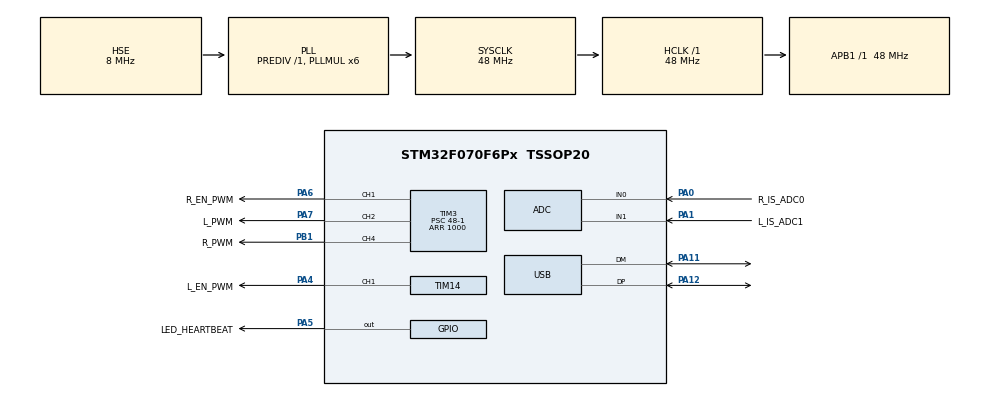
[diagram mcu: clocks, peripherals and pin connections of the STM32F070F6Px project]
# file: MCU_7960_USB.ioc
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ADC.ClockPrescaler=ADC_CLOCK_SYNC_PCLK_DIV4
ADC.ContinuousConvMode=DISABLE
ADC.ExternalTrigConv=ADC_SOFTWARE_START
ADC.ExternalTrigConvEdge=ADC_EXTERNALTRIGCONVEDGE_NONE
ADC.Overrun=ADC_OVR_DATA_OVERWRITTEN
Mcu.Family=STM32F0
Mcu.Name=STM32F070F6Px
Mcu.Package=TSSOP20
NVIC.ADC1_IRQn=true\:0\:0\:false\:false\:true\:true\:true\:true
NVIC.TIM3_IRQn=true\:0\:0\:false\:false\:true\:true\:true\:true
NVIC.USB_IRQn=true\:0\:0\:false\:false\:true\:false\:true\:true
PA0.GPIO_Label=R_IS_ADC0
PA0.Mode=IN0
PA0.Signal=ADC_IN0
PA1.GPIO_Label=L_IS_ADC1
PA1.Mode=IN1
PA1.Signal=ADC_IN1
PA11.Mode=Device
PA11.Signal=USB_DM
PA12.Mode=Device
PA12.Signal=USB_DP
PA13.Mode=Serial_Wire
PA13.Signal=SYS_SWDIO
PA14.Mode=Serial_Wire
PA14.Signal=SYS_SWCLK
PA4.GPIO_Label=L_EN_PWM
PA4.Signal=S_TIM14_CH1
PA5.GPIO_Label=LED_HEARTBEAT
PA5.GPIO_ModeDefaultOutputPP=GPIO_MODE_OUTPUT_OD
PA5.GPIO_PuPd=GPIO_NOPULL
PA5.Signal=GPIO_Output
PA6.GPIO_Label=R_EN_PWM
PA6.Signal=S_TIM3_CH1
PA7.GPIO_Label=L_PWM
PA7.Signal=S_TIM3_CH2
PB1.GPIO_Label=R_PWM
PB1.Signal=S_TIM3_CH4
PF0-OSC_IN.Mode=HSE-External-Oscillator
PF0-OSC_IN.Signal=RCC_OSC_IN
PF1-OSC_OUT.Mode=HSE-External-Oscillator
PF1-OSC_OUT.Signal=RCC_OSC_OUT
ProjectManager.HeapSize=0x150
ProjectManager.StackSize=0x300
ProjectManager.TargetToolchain=Makefile
RCC.AHBFreq_Value=48000000
RCC.APB1Freq_Value=48000000
RCC.APB1TimFreq_Value=48000000
RCC.HCLKFreq_Value=48000000
RCC.PLLMUL=RCC_PLL_MUL6
RCC.SYSCLKFreq_VALUE=48000000
RCC.SYSCLKSource=RCC_SYSCLKSOURCE_PLLCLK
SH.S_TIM14_CH1.0=TIM14_CH1,PWM Generation1 CH1
SH.S_TIM3_CH1.0=TIM3_CH1,PWM Generation1 CH1
SH.S_TIM3_CH2.0=TIM3_CH2,PWM Generation2 CH2
SH.S_TIM3_CH4.0=TIM3_CH4,PWM Generation4 CH4
TIM1.AutoReloadPreload=TIM_AUTORELOAD_PRELOAD_ENABLE
TIM1.Period=5000
TIM1.Prescaler=48-1
TIM14.AutoReloadPreload=TIM_AUTORELOAD_PRELOAD_ENABLE
TIM14.Channel=TIM_CHANNEL_1
TIM14.OCPolarity_1=TIM_OCPOLARITY_LOW
TIM14.Period=1000
TIM14.Prescaler=48-1
TIM3.AutoReloadPreload=TIM_AUTORELOAD_PRELOAD_ENABLE
TIM3.Channel-PWM\ Generation1\ CH1=TIM_CHANNEL_1
TIM3.Channel-PWM\ Generation2\ CH2=TIM_CHANNEL_2
TIM3.Channel-PWM\ Generation4\ CH4=TIM_CHANNEL_4
TIM3.OCPolarity_1=TIM_OCPOLARITY_LOW
TIM3.OCPolarity_4=TIM_OCPOLARITY_LOW
TIM3.Period=1000
TIM3.Prescaler=48-1
USB_DEVICE.APP_RX_DATA_SIZE=512
USB_DEVICE.APP_TX_DATA_SIZE=512
USB_DEVICE.CLASS_NAME_FS=CDC
USB_DEVICE.VirtualMode=Cdc
USB_DEVICE.VirtualModeFS=Cdc_FS
VP_SYS_VS_PINREMAP.Mode=PINREMAP
VP_TIM14_VS_ClockSourceINT.Mode=Enable_Timer
VP_TIM1_VS_ClockSourceINT.Mode=Internal
VP_TIM3_VS_ClockSourceINT.Mode=Internal
VP_USB_DEVICE_VS_USB_DEVICE_CDC_FS.Mode=CDC_FS
VP_WWDG_VS_WWDG.Mode=WWDG_Activate
WWDG.Prescaler=WWDG_PRESCALER_8
board=custom

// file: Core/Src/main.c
/* USER CODE BEGIN Header */
/**
  ******************************************************************************
  * @file           : main.c
  * @brief          : Main program body
  ******************************************************************************
  * @attention
  *
  * Copyright (c) 2024 STMicroelectronics.
  * All rights reserved.
  *
  * This software is licensed under terms that can be found in the LICENSE file
  * in the root directory of this software component.
  * If no LICENSE file comes with this software, it is provided AS-IS.
  *
  ******************************************************************************
  */
/* USER CODE END Header */
#include "main.h"
#include "usb_device.h"

/* USER CODE BEGIN Includes */
#include "Comms_Controller.h"
#include "MCU_7960_USB.h"
/* USER CODE END Includes */

ADC_HandleTypeDef hadc;

TIM_HandleTypeDef htim1;
TIM_HandleTypeDef htim3;
TIM_HandleTypeDef htim14;

WWDG_HandleTypeDef hwwdg;

void SystemClock_Config(void);
static void MX_GPIO_Init(void);
static void MX_ADC_Init(void);
static void MX_TIM3_Init(void);
static void MX_TIM14_Init(void);
static void MX_TIM1_Init(void);

int main(void)
{

  /* MCU Configuration--------------------------------------------------------*/

  /* Reset of all peripherals, Initializes the Flash interface and the Systick. */
  HAL_Init();

  /* Configure the system clock */
  SystemClock_Config();

  /* USER CODE BEGIN SysInit */
  MX_GPIO_Init();
  Comms_Controller_Reset_USB();

  /* USER CODE END SysInit */

  /* Initialize all configured peripherals */
  MX_ADC_Init();
  MX_TIM3_Init();
  MX_TIM14_Init();
  MX_USB_DEVICE_Init();
  MX_TIM1_Init();
  /* USER CODE BEGIN 2 */
  MCU_7960_USB_Initialise();
  HAL_TIM_Base_Start_IT(&htim3);

  /* USER CODE END 2 */

  /* Infinite loop */
  while (1)
  {

    /* USER CODE BEGIN 3 */
    MCU_7960_USB_Main();

  }
  /* USER CODE END 3 */
}

void SystemClock_Config(void)
{
  RCC_OscInitTypeDef RCC_OscInitStruct = {0};
  RCC_ClkInitTypeDef RCC_ClkInitStruct = {0};
  RCC_PeriphCLKInitTypeDef PeriphClkInit = {0};

  /** Initializes the RCC Oscillators according to the specified parameters
  * in the RCC_OscInitTypeDef structure.
  */
  RCC_OscInitStruct.OscillatorType = RCC_OSCILLATORTYPE_HSE;
  RCC_OscInitStruct.HSEState = RCC_HSE_ON;
  RCC_OscInitStruct.PLL.PLLState = RCC_PLL_ON;
  RCC_OscInitStruct.PLL.PLLSource = RCC_PLLSOURCE_HSE;
  RCC_OscInitStruct.PLL.PLLMUL = RCC_PLL_MUL6;
  RCC_OscInitStruct.PLL.PREDIV = RCC_PREDIV_DIV1;
  if (HAL_RCC_OscConfig(&RCC_OscInitStruct) != HAL_OK)
  {
    Error_Handler();
  }

  /** Initializes the CPU, AHB and APB buses clocks
  */
  RCC_ClkInitStruct.ClockType = RCC_CLOCKTYPE_HCLK|RCC_CLOCKTYPE_SYSCLK
                              |RCC_CLOCKTYPE_PCLK1;
  RCC_ClkInitStruct.SYSCLKSource = RCC_SYSCLKSOURCE_PLLCLK;
  RCC_ClkInitStruct.AHBCLKDivider = RCC_SYSCLK_DIV1;
  RCC_ClkInitStruct.APB1CLKDivider = RCC_HCLK_DIV1;

  if (HAL_RCC_ClockConfig(&RCC_ClkInitStruct, FLASH_LATENCY_1) != HAL_OK)
  {
    Error_Handler();
  }
  PeriphClkInit.PeriphClockSelection = RCC_PERIPHCLK_USB;
  PeriphClkInit.UsbClockSelection = RCC_USBCLKSOURCE_PLL;

  if (HAL_RCCEx_PeriphCLKConfig(&PeriphClkInit) != HAL_OK)
  {
    Error_Handler();
  }
}

static void MX_ADC_Init(void)
{

  ADC_ChannelConfTypeDef sConfig = {0};

  /** Configure the global features of the ADC (Clock, Resolution, Data Alignment and number of conversion)
  */
  hadc.Instance = ADC1;
  hadc.Init.ClockPrescaler = ADC_CLOCK_SYNC_PCLK_DIV4;
  hadc.Init.Resolution = ADC_RESOLUTION_12B;
  hadc.Init.DataAlign = ADC_DATAALIGN_RIGHT;
  hadc.Init.ScanConvMode = ADC_SCAN_DIRECTION_FORWARD;
  hadc.Init.EOCSelection = ADC_EOC_SINGLE_CONV;
  hadc.Init.LowPowerAutoWait = DISABLE;
  hadc.Init.LowPowerAutoPowerOff = DISABLE;
  hadc.Init.ContinuousConvMode = DISABLE;
  hadc.Init.DiscontinuousConvMode = DISABLE;
  hadc.Init.ExternalTrigConv = ADC_SOFTWARE_START;
  hadc.Init.ExternalTrigConvEdge = ADC_EXTERNALTRIGCONVEDGE_NONE;
  hadc.Init.DMAContinuousRequests = DISABLE;
  hadc.Init.Overrun = ADC_OVR_DATA_OVERWRITTEN;
  if (HAL_ADC_Init(&hadc) != HAL_OK)
  {
    Error_Handler();
  }

  /** Configure for the selected ADC regular channel to be converted.
  */
  sConfig.Channel = ADC_CHANNEL_0;
  sConfig.Rank = ADC_RANK_CHANNEL_NUMBER;
  sConfig.SamplingTime = ADC_SAMPLETIME_1CYCLE_5;
  if (HAL_ADC_ConfigChannel(&hadc, &sConfig) != HAL_OK)
  {
    Error_Handler();
  }

  /** Configure for the selected ADC regular channel to be converted.
  */
  sConfig.Channel = ADC_CHANNEL_1;
  if (HAL_ADC_ConfigChannel(&hadc, &sConfig) != HAL_OK)
  {
    Error_Handler();
  }
  /* USER CODE BEGIN ADC_Init 2 */
  HAL_ADC_Start_IT(&hadc);  // start the sequence conversions

  /* USER CODE END ADC_Init 2 */

}

static void MX_TIM1_Init(void)
{

  TIM_ClockConfigTypeDef sClockSourceConfig = {0};
  TIM_MasterConfigTypeDef sMasterConfig = {0};

  htim1.Instance = TIM1;
  htim1.Init.Prescaler = 48-1;
  htim1.Init.CounterMode = TIM_COUNTERMODE_UP;
  htim1.Init.Period = 5000;
  htim1.Init.ClockDivision = TIM_CLOCKDIVISION_DIV1;
  htim1.Init.RepetitionCounter = 0;
  htim1.Init.AutoReloadPreload = TIM_AUTORELOAD_PRELOAD_ENABLE;
  if (HAL_TIM_Base_Init(&htim1) != HAL_OK)
  {
    Error_Handler();
  }
  sClockSourceConfig.ClockSource = TIM_CLOCKSOURCE_INTERNAL;
  if (HAL_TIM_ConfigClockSource(&htim1, &sClockSourceConfig) != HAL_OK)
  {
    Error_Handler();
  }
  sMasterConfig.MasterOutputTrigger = TIM_TRGO_RESET;
  sMasterConfig.MasterSlaveMode = TIM_MASTERSLAVEMODE_DISABLE;
  if (HAL_TIMEx_MasterConfigSynchronization(&htim1, &sMasterConfig) != HAL_OK)
  {
    Error_Handler();
  }

}

static void MX_TIM3_Init(void)
{

  TIM_ClockConfigTypeDef sClockSourceConfig = {0};
  TIM_MasterConfigTypeDef sMasterConfig = {0};
  TIM_OC_InitTypeDef sConfigOC = {0};

  htim3.Instance = TIM3;
  htim3.Init.Prescaler = 48-1;
  htim3.Init.CounterMode = TIM_COUNTERMODE_UP;
  htim3.Init.Period = 1000;
  htim3.Init.ClockDivision = TIM_CLOCKDIVISION_DIV1;
  htim3.Init.AutoReloadPreload = TIM_AUTORELOAD_PRELOAD_ENABLE;
  if (HAL_TIM_Base_Init(&htim3) != HAL_OK)
  {
    Error_Handler();
  }
  sClockSourceConfig.ClockSource = TIM_CLOCKSOURCE_INTERNAL;
  if (HAL_TIM_ConfigClockSource(&htim3, &sClockSourceConfig) != HAL_OK)
  {
    Error_Handler();
  }
  if (HAL_TIM_PWM_Init(&htim3) != HAL_OK)
  {
    Error_Handler();
  }
  sMasterConfig.MasterOutputTrigger = TIM_TRGO_RESET;
  sMasterConfig.MasterSlaveMode = TIM_MASTERSLAVEMODE_DISABLE;
  if (HAL_TIMEx_MasterConfigSynchronization(&htim3, &sMasterConfig) != HAL_OK)
  {
    Error_Handler();
  }
  sConfigOC.OCMode = TIM_OCMODE_PWM1;
  sConfigOC.Pulse = 0;
  sConfigOC.OCPolarity = TIM_OCPOLARITY_LOW;
  sConfigOC.OCFastMode = TIM_OCFAST_DISABLE;
  if (HAL_TIM_PWM_ConfigChannel(&htim3, &sConfigOC, TIM_CHANNEL_1) != HAL_OK)
  {
    Error_Handler();
  }
  sConfigOC.OCPolarity = TIM_OCPOLARITY_HIGH;
  if (HAL_TIM_PWM_ConfigChannel(&htim3, &sConfigOC, TIM_CHANNEL_2) != HAL_OK)
  {
    Error_Handler();
  }
  sConfigOC.OCPolarity = TIM_OCPOLARITY_LOW;
  if (HAL_TIM_PWM_ConfigChannel(&htim3, &sConfigOC, TIM_CHANNEL_4) != HAL_OK)
  {
    Error_Handler();
  }
  HAL_TIM_MspPostInit(&htim3);

}

static void MX_TIM14_Init(void)
{

  TIM_OC_InitTypeDef sConfigOC = {0};

  htim14.Instance = TIM14;
  htim14.Init.Prescaler = 48-1;
  htim14.Init.CounterMode = TIM_COUNTERMODE_UP;
  htim14.Init.Period = 1000;
  htim14.Init.ClockDivision = TIM_CLOCKDIVISION_DIV1;
  htim14.Init.AutoReloadPreload = TIM_AUTORELOAD_PRELOAD_ENABLE;
  if (HAL_TIM_Base_Init(&htim14) != HAL_OK)
  {
    Error_Handler();
  }
  if (HAL_TIM_PWM_Init(&htim14) != HAL_OK)
  {
    Error_Handler();
  }
  sConfigOC.OCMode = TIM_OCMODE_PWM1;
  sConfigOC.Pulse = 0;
  sConfigOC.OCPolarity = TIM_OCPOLARITY_LOW;
  sConfigOC.OCFastMode = TIM_OCFAST_DISABLE;
  if (HAL_TIM_PWM_ConfigChannel(&htim14, &sConfigOC, TIM_CHANNEL_1) != HAL_OK)
  {
    Error_Handler();
  }
  HAL_TIM_MspPostInit(&htim14);

}

void MX_WWDG_Init(void)
{

  hwwdg.Instance = WWDG;
  hwwdg.Init.Prescaler = WWDG_PRESCALER_8;
  hwwdg.Init.Window = 64;
  hwwdg.Init.Counter = 64;
  hwwdg.Init.EWIMode = WWDG_EWI_DISABLE;
  if (HAL_WWDG_Init(&hwwdg) != HAL_OK)
  {
    Error_Handler();
  }

}

static void MX_GPIO_Init(void)
{
  GPIO_InitTypeDef GPIO_InitStruct = {0};

  /* GPIO Ports Clock Enable */
  __HAL_RCC_GPIOF_CLK_ENABLE();
  __HAL_RCC_GPIOA_CLK_ENABLE();
  __HAL_RCC_GPIOB_CLK_ENABLE();

  /*Configure GPIO pin Output Level */
  HAL_GPIO_WritePin(LED_HEARTBEAT_GPIO_Port, LED_HEARTBEAT_Pin, GPIO_PIN_RESET);

  /*Configure GPIO pin : LED_HEARTBEAT_Pin */
  GPIO_InitStruct.Pin = LED_HEARTBEAT_Pin;
  GPIO_InitStruct.Mode = GPIO_MODE_OUTPUT_OD;
  GPIO_InitStruct.Pull = GPIO_NOPULL;
  GPIO_InitStruct.Speed = GPIO_SPEED_FREQ_LOW;
  HAL_GPIO_Init(LED_HEARTBEAT_GPIO_Port, &GPIO_InitStruct);

}

void Error_Handler(void)
{
  __disable_irq();
  while (1)
  {
  }
}
